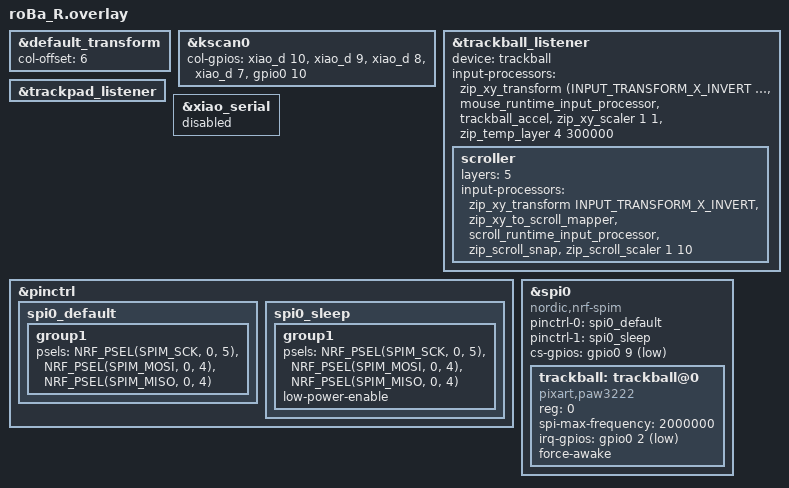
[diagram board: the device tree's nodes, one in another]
#include "roBa.dtsi"
#include <input/processors.dtsi>
#include <dt-bindings/zmk/input_transform.h>
#include <zephyr/dt-bindings/input/input-event-codes.h>
#include <input/processors/runtime-input-processor.dtsi>
#include <behaviors/battery_history_request.dtsi>

&default_transform {
    col-offset = <6>;
};

&kscan0 {
    col-gpios
        = <&xiao_d 10 GPIO_ACTIVE_HIGH>
        , <&xiao_d 9 GPIO_ACTIVE_HIGH>
        , <&xiao_d 8 GPIO_ACTIVE_HIGH>
        , <&xiao_d 7 GPIO_ACTIVE_HIGH>
        , <&gpio0 10 GPIO_ACTIVE_HIGH>
        ;
};

&trackball_listener {
    status = "okay";
    device = <&trackball>;
    input-processors =
        <&zip_xy_transform (INPUT_TRANSFORM_X_INVERT | INPUT_TRANSFORM_Y_INVERT)>,
        <&mouse_runtime_input_processor>,
        <&trackball_accel>,
        <&zip_xy_scaler 1 1>,
        <&zip_temp_layer 4 300000>;

    scroller {
        layers = <5>;
        input-processors = 
            <&zip_xy_transform INPUT_TRANSFORM_X_INVERT>,
            <&zip_xy_to_scroll_mapper>,
            <&scroll_runtime_input_processor>,
            <&zip_scroll_snap>,
            <&zip_scroll_scaler 1 10>;
    };
};

&trackpad_listener {
    status = "okay";
};

&xiao_serial { status = "disabled"; };

&pinctrl {
    spi0_default: spi0_default {
        group1 {
            psels = <NRF_PSEL(SPIM_SCK, 0, 5)>,
                <NRF_PSEL(SPIM_MOSI, 0, 4)>,
                <NRF_PSEL(SPIM_MISO, 0, 4)>;
        };
    };

    spi0_sleep: spi0_sleep {
        group1 {
            psels = <NRF_PSEL(SPIM_SCK, 0, 5)>,
                <NRF_PSEL(SPIM_MOSI, 0, 4)>,
                <NRF_PSEL(SPIM_MISO, 0, 4)>;
            low-power-enable;
        };
    };
};

&spi0 {
    status = "okay";
    compatible = "nordic,nrf-spim";
    pinctrl-0 = <&spi0_default>;
    pinctrl-1 = <&spi0_sleep>;
    pinctrl-names = "default", "sleep";
    cs-gpios = <&gpio0 9 GPIO_ACTIVE_LOW>;

    trackball: trackball@0 {
        status = "okay";
        compatible = "pixart,paw3222";
        reg = <0>;
        spi-max-frequency = <2000000>;
        irq-gpios = <&gpio0 2 (GPIO_ACTIVE_LOW | GPIO_PULL_UP)>;
        force-awake;
    };
};
